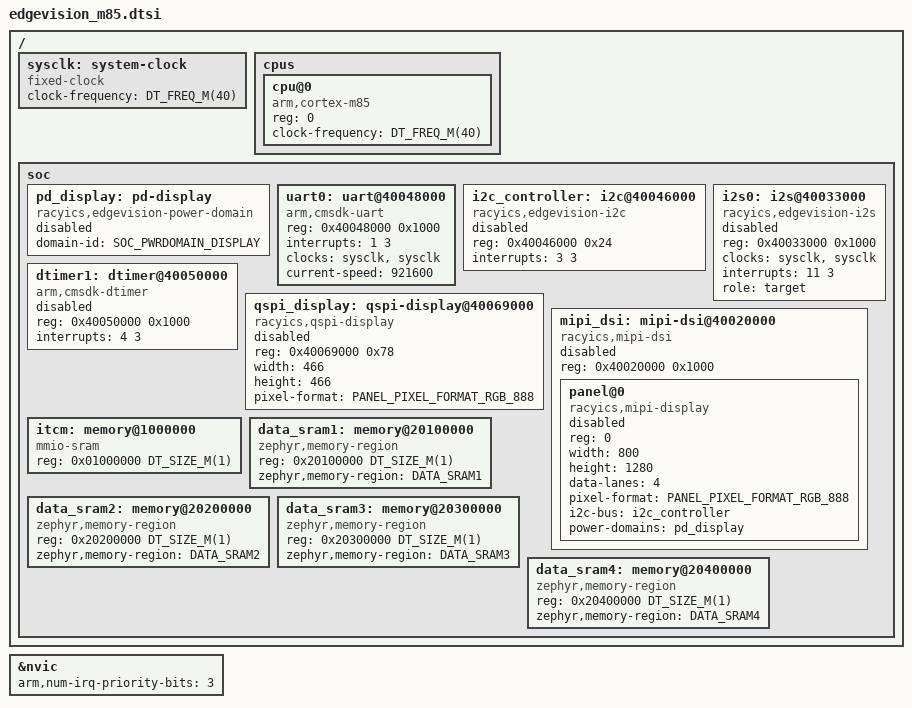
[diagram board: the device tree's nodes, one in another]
/*
 * Copyright (c) 2026 sensry.io
 *
 * SPDX-License-Identifier: Apache-2.0
 */

#include <mem.h>
#include <arm/armv8.1-m.dtsi>
#include <freq.h>
#include <zephyr/dt-bindings/display/panel.h>
#include <zephyr/dt-bindings/power/edgevision_power.h>

/ {
	sysclk: system-clock {
		compatible = "fixed-clock";
		clock-frequency = <DT_FREQ_M(40)>;
		#clock-cells = <0>;
	};

	cpus {
		#address-cells = <1>;
		#size-cells = <0>;

		cpu@0 {
			device_type = "cpu";
			compatible = "arm,cortex-m85";
			reg = <0>;
			clock-frequency = <DT_FREQ_M(40)>;
			#address-cells = <1>;
			#size-cells = <1>;
		};

	};

	soc {
		pd_display: pd-display {
			compatible = "racyics,edgevision-power-domain";
			domain-id = <SOC_PWRDOMAIN_DISPLAY>;
			#power-domain-cells = <0>;
			status = "disabled";
		};

		uart0: uart@40048000 {
			compatible = "arm,cmsdk-uart";
			reg = <0x40048000 0x1000>;
			interrupts = <1 3>;
			clocks = <&sysclk &sysclk>;
			current-speed = <921600>;
			status = "okay";
		};

		i2c_controller: i2c@40046000 {
			compatible = "racyics,edgevision-i2c";
			reg = <0x40046000 0x24>;
			interrupts = <3 3>;
			#address-cells = <1>;
			#size-cells = <0>;
			status = "disabled";
		};

		i2s0: i2s@40033000 {
			compatible = "racyics,edgevision-i2s";
			reg = <0x40033000 0x1000>;
			clocks = <&sysclk &sysclk>;
			interrupts = <11 3>;
			role = "target";
			status = "disabled";
		};

		dtimer1: dtimer@40050000 {
			compatible = "arm,cmsdk-dtimer";
			reg = <0x40050000 0x1000>;
			interrupts = <4 3>;
			status = "disabled";
		};

		qspi_display: qspi-display@40069000 {
			compatible = "racyics,qspi-display";
			reg = <0x40069000 0x78>;
			width = <466>;
			height = <466>;
			pixel-format = <PANEL_PIXEL_FORMAT_RGB_888>;
			status = "disabled";
		};

		mipi_dsi: mipi-dsi@40020000 {
			reg = <0x40020000 0x1000>;
			compatible = "racyics,mipi-dsi";
			#address-cells = <1>;
			#size-cells = <0>;
			status = "disabled";

			panel@0 {
				compatible = "racyics,mipi-display";
				reg = <0>;
				width = <800>;
				height = <1280>;
				data-lanes = <4>;
				pixel-format = <PANEL_PIXEL_FORMAT_RGB_888>;
				i2c-bus = <&i2c_controller>;
				status = "disabled";
				power-domains = <&pd_display>;
			};
		};

		itcm: memory@1000000 {
			compatible = "mmio-sram";
			reg = <0x01000000 DT_SIZE_M(1)>;
		};
		data_sram1: memory@20100000 {
			compatible = "zephyr,memory-region", "mmio-sram";
			reg = <0x20100000 DT_SIZE_M(1)>;
			zephyr,memory-region = "DATA_SRAM1";
			status = "okay";
		};
		data_sram2: memory@20200000 {
			compatible = "zephyr,memory-region", "mmio-sram";
			reg = <0x20200000 DT_SIZE_M(1)>;
			zephyr,memory-region = "DATA_SRAM2";
			status = "okay";
		};
		data_sram3: memory@20300000 {
			compatible = "zephyr,memory-region", "mmio-sram";
			reg = <0x20300000 DT_SIZE_M(1)>;
			zephyr,memory-region = "DATA_SRAM3";
			status = "okay";
		};
		data_sram4: memory@20400000 {
			compatible = "zephyr,memory-region", "mmio-sram";
			reg = <0x20400000 DT_SIZE_M(1)>;
			zephyr,memory-region = "DATA_SRAM4";
			status = "okay";
		};

	};
};

&nvic {
	arm,num-irq-priority-bits = <3>;
};
